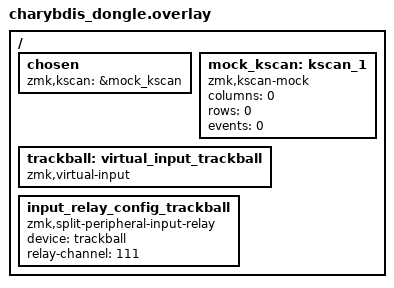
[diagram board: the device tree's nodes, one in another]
#include "charybdis.dtsi"

/ {
    chosen {
        zmk,kscan = &mock_kscan;
    };

    mock_kscan: kscan_1 {
        compatible = "zmk,kscan-mock";
        columns = <0>;
        rows = <0>;
        events = <0>;
    };
};

/ {
    trackball: virtual_input_trackball {
		compatible = "zmk,virtual-input";
	};

	input_relay_config_trackball {
		compatible = "zmk,split-peripheral-input-relay";
        device = <&trackball>;
		relay-channel = <111>;
	};
};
